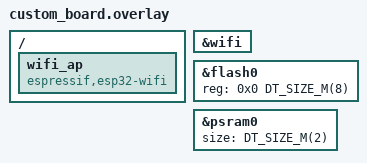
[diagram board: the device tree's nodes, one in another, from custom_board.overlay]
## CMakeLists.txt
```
# SPDX-License-Identifier: Apache-2.0
cmake_minimum_required(VERSION 3.20.0)
find_package(Zephyr REQUIRED HINTS $ENV{ZEPHYR_BASE})

project(http_get)

target_sources(app PRIVATE
  ./src/http_get.c
  # src/settings_thread.c
  ./src/nvs_usage.c
)

include(${ZEPHYR_BASE}/samples/net/common/common.cmake)

set(gen_dir ${ZEPHYR_BINARY_DIR}/include/generated/)

generate_inc_file_for_target(
    app
    src/globalsign_r1.der
    ${gen_dir}/globalsign_r1.der.inc
    )
```

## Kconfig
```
#
# Copyright (c) 2025 Ezurio
#
# SPDX-License-Identifier: Apache-2.0
#

source "samples/net/common/Kconfig"
source "Kconfig.zephyr"

config SAMPLE_USE_SPIRAM
	bool "Use SPIRAM to allocate MbedTLS heap, network stacks and some variables"
	default y
	depends on ESP_SPIRAM
	select ESP32_WIFI_NET_ALLOC_SPIRAM
	select MBEDTLS_HEAP_CUSTOM_SECTION
```

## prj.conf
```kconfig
# General config
CONFIG_MAIN_STACK_SIZE=4096
CONFIG_REQUIRES_FULL_LIBC=y
CONFIG_HEAP_MEM_POOL_SIZE=100000

CONFIG_ZVFS_POLL_MAX=4
# Networking config
CONFIG_NETWORKING=y
CONFIG_NET_IPV4=y
CONFIG_NET_IPV6=y
CONFIG_NET_TCP=y
CONFIG_NET_SOCKETS=y

CONFIG_POSIX_API=y

# CONFIG_DNS_RESOLVER=y
# CONFIG_DNS_SERVER_IP_ADDRESSES=y
# CONFIG_DNS_SERVER1="192.0.2.2"

# Network driver config
CONFIG_TEST_RANDOM_GENERATOR=y

# Network address config
CONFIG_NET_CONFIG_SETTINGS=y
CONFIG_NET_CONFIG_NEED_IPV4=y
CONFIG_NET_CONFIG_MY_IPV4_ADDR="192.0.2.1"
CONFIG_NET_CONFIG_PEER_IPV4_ADDR="192.0.2.2"
CONFIG_NET_CONFIG_MY_IPV4_GW=""

# Network debug config
CONFIG_NET_LOG=y

# Network (Configs)
# CONFIG_NET_TCP_WORKQ_STACK_SIZE=4096
CONFIG_NET_BUF_DATA_SIZE=256
CONFIG_NET_TX_STACK_SIZE=4096
CONFIG_NET_RX_STACK_SIZE=4096
# Networking
CONFIG_NETWORKING=y
CONFIG_NET_CONFIG_SETTINGS=y
CONFIG_NET_MGMT_EVENT_QUEUE_SIZE=10
# CONFIG_NET_TCP_WORKQ_STACK_SIZE=8192
CONFIG_NET_CONFIG_AUTO_INIT=n
# This is the maximum number of connections that can be active at any given time.
CONFIG_NET_MAX_CONN=12
CONFIG_NET_DHCPV4=y
CONFIG_NET_IPV4=y
CONFIG_NET_IF_MAX_IPV4_COUNT=1
CONFIG_NET_IPV6=n
CONFIG_NET_SOCKETS=y
CONFIG_NET_L2_ETHERNET=y
CONFIG_NET_L2_WIFI_MGMT=y
CONFIG_NET_MGMT=y
CONFIG_NET_MGMT_EVENT=y
CONFIG_NET_MGMT_EVENT_INFO=y
CONFIG_NET_MGMT_EVENT_STACK_SIZE=2048
CONFIG_NET_PKT_RX_COUNT=12
CONFIG_NET_PKT_TX_COUNT=12
CONFIG_NET_TCP=y
CONFIG_NET_MAX_CONTEXTS=6
CONFIG_NET_UDP=y

# Networking (DNS)
CONFIG_DNS_RESOLVER=y
CONFIG_DNS_RESOLVER_AI_MAX_ENTRIES=3

CONFIG_WIFI=y
CONFIG_WIFI_ESP32=y
CONFIG_ESP32_WIFI_STA_AUTO_DHCPV4=y
CONFIG_ESP32_WIFI_STA_RECONNECT=y
CONFIG_ESP32_WIFI_AP_STA_MODE=n
# CONFIG_WIFI_NM=y
# CONFIG_WIFI_NM_MAX_MANAGED_INTERFACES=2
# # Networking (Connection Manager)
# CONFIG_NET_CONNECTION_MANAGER=y
# CONFIG_NET_CONNECTION_MANAGER_CONNECTIVITY_WIFI_MGMT=y

# Shell
CONFIG_SHELL=n
CONFIG_SYS_HEAP_RUNTIME_STATS=y
# CONFIG_NET_STATISTICS=y
# CONFIG_NET_STATISTICS_TCP=y
# CONFIG_NET_STATISTICS_USER_API=y
CONFIG_THREAD_NAME=y
CONFIG_THREAD_STACK_INFO=n
# CONFIG_NET_SHELL=y
# CONFIG_NET_L2_WIFI_SHELL=y

# TLS configuration
CONFIG_MBEDTLS=y
CONFIG_MBEDTLS_BUILTIN=y
CONFIG_MBEDTLS_ENABLE_HEAP=y
# 60KB for MbedTLS HEAP
CONFIG_MBEDTLS_HEAP_SIZE=61440
CONFIG_MBEDTLS_SSL_MAX_CONTENT_LEN=7168
# CONFIG_MBEDTLS_SSL_MAX_CONTENT_LEN=7168
CONFIG_MBEDTLS_HASH_ALL_ENABLED=y
CONFIG_MBEDTLS_CMAC=y

CONFIG_NET_SOCKETS_SOCKOPT_TLS=y

# Debugging options
# CONFIG_MBEDTLS_DEBUG=y
# CONFIG_MBEDTLS_LOG_LEVEL_INF=y

# Logging
CONFIG_LOG=y
CONFIG_LOG_MODE_MINIMAL=y
CONFIG_LOG_MODE_IMMEDIATE=y
# CONFIG_LOG_BUFFER_SIZE=8000
# CONFIG_LOG_PROCESS_THREAD_STACK_SIZE=4096

CONFIG_NVS=y
# CONFIG_SETTINGS=y
# CONFIG_SETTINGS_RUNTIME=y
# CONFIG_SETTINGS_NVS=y

# Flash configuration settings.
CONFIG_FLASH=y
CONFIG_FLASH_MAP=y
CONFIG_FLASH_PAGE_LAYOUT=y
CONFIG_STREAM_FLASH=y
CONFIG_MPU_ALLOW_FLASH_WRITE=y
```

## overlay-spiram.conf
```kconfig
# SPIRAM configuration
CONFIG_ESP_SPIRAM=y
CONFIG_ESP32S3_DATA_CACHE_64KB=y
# CONFIG_SPIRAM_FETCH_INSTRUCTIONS=y
# CONFIG_SPIRAM_RODATA=y
CONFIG_ESP_SPIRAM_HEAP_SIZE=524288
# CONFIG_ESP32_WIFI_NET_ALLOC_SPIRAM=y
CONFIG_ESP_SPIRAM_MEMTEST=y
CONFIG_SPIRAM_MODE_QUAD=y
CONFIG_SPIRAM_SPEED_40M=y
# CONFIG_MBEDTLS_HEAP_CUSTOM_SECTION=y
```

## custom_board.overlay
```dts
&wifi {
	status = "okay";
};

/ {
	wifi_ap: wifi_ap {
		compatible = "espressif,esp32-wifi";
		status = "okay";
	};
};

/* 8MB flash */
&flash0 {
	reg = <0x0 DT_SIZE_M(8)>;
};

/* 2MB psram */
&psram0 {
	size = <DT_SIZE_M(2)>;
};
```

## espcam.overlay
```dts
&wifi {
	status = "okay";
};

/ {
	wifi_ap: wifi_ap {
		compatible = "espressif,esp32-wifi";
		status = "okay";
	};
};
```

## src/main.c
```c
#include <zephyr/kernel.h>
#include <zephyr/debug/coredump.h>

int main(int argc, char *argv[])
{
	printk("Init app\n");
	return 0;
}
```

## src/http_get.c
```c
/*
 * Copyright (c) 2017 Linaro Limited
 *
 * SPDX-License-Identifier: Apache-2.0
 */

#include <stdio.h>
#include <stdlib.h>

#if !defined(__ZEPHYR__)

#include <netinet/in.h>
#include <sys/socket.h>
#include <arpa/inet.h>
#include <unistd.h>
#include <netdb.h>

#else

#include <zephyr/net/socket.h>
#include <zephyr/kernel.h>
#include <zephyr/net/wifi_mgmt.h>

#if defined(CONFIG_NET_SOCKETS_SOCKOPT_TLS)
#include <zephyr/net/tls_credentials.h>
#include "ca_certificate.h"
#endif

#include <zephyr/logging/log.h>
LOG_MODULE_REGISTER(app, LOG_LEVEL_DBG);

#include "net_sample_common.h"

#endif /* __ZEPHYR__ */

#define MACSTR "%02X:%02X:%02X:%02X:%02X:%02X"

#define NET_EVENT_WIFI_MASK (NET_EVENT_WIFI_CONNECT_RESULT | NET_EVENT_WIFI_DISCONNECT_RESULT)

/* STA Mode Configuration */
#define WIFI_SSID "NETUNO"   /* Replace `SSID` with WiFi ssid. */
#define WIFI_PSK  "11311118" /* Replace `PASSWORD` with Router password. */

static struct net_if *sta_iface;
static struct wifi_connect_req_params sta_config;

/* HTTP server to connect to */
#define HTTP_HOST "google.com"
/* Port to connect to, as string */
#if defined(CONFIG_NET_SOCKETS_SOCKOPT_TLS)
#define HTTP_PORT "443"
#else
#define HTTP_PORT "80"
#endif
/* HTTP path to request */
#define HTTP_PATH "/"

#define SSTRLEN(s) (sizeof(s) - 1)
#define CHECK(r)                                                                                   \
	{                                                                                          \
		if (r < 0) {                                                                       \
			ret = r;                                                                   \
			LOG_DBG("Error: %d", (int)r);                                              \
			goto cleanup;                                                              \
		}                                                                                  \
	}

#define REQUEST "GET " HTTP_PATH " HTTP/1.1\r\nHost: " HTTP_HOST "\r\n\r\n"

#if defined(CONFIG_SAMPLE_USE_SPIRAM)
#define RAM_SECTION __attribute__((section(".ext_ram.bss")))
#else
#define RAM_SECTION
#endif

#define RESPONSE_BUFFER_SIZE 128
RAM_SECTION static char response[RESPONSE_BUFFER_SIZE];

static struct net_mgmt_event_callback cb;
K_SEM_DEFINE(sem_connected_to_internet, 0, 1);

static void wifi_event_handler(struct net_mgmt_event_callback *cb, uint32_t mgmt_event,
			       struct net_if *iface)
{
	switch (mgmt_event) {
	case NET_EVENT_WIFI_CONNECT_RESULT: {
		LOG_DBG("Connected to %s", WIFI_SSID);
		k_sem_give(&sem_connected_to_internet);
		break;
	}
	case NET_EVENT_WIFI_DISCONNECT_RESULT: {
		LOG_DBG("Disconnected from %s", WIFI_SSID);
		break;
	}
	default:
		break;
	}
}
void dump_addrinfo(const struct addrinfo *ai)
{
	LOG_DBG("addrinfo @%p: ai_family=%d, ai_socktype=%d, ai_protocol=%d, "
		"sa_family=%d, sin_port=%x",
		ai, ai->ai_family, ai->ai_socktype, ai->ai_protocol, ai->ai_addr->sa_family,
		ntohs(((struct sockaddr_in *)ai->ai_addr)->sin_port));
}

static int connect_to_wifi(void)
{
	if (!sta_iface) {
		LOG_DBG("STA: interface no initialized");
		return -EIO;
	}

	sta_config.ssid = (const uint8_t *)WIFI_SSID;
	sta_config.ssid_length = strlen(WIFI_SSID);
	sta_config.psk = (const uint8_t *)WIFI_PSK;
	sta_config.psk_length = strlen(WIFI_PSK);
	sta_config.security = WIFI_SECURITY_TYPE_PSK;
	sta_config.channel = WIFI_CHANNEL_ANY;
	sta_config.band = WIFI_FREQ_BAND_2_4_GHZ;

	LOG_DBG("Connecting to SSID: %s", sta_config.ssid);

	int ret = net_mgmt(NET_REQUEST_WIFI_CONNECT, sta_iface, &sta_config,
			   sizeof(struct wifi_connect_req_params));
	if (ret) {
		LOG_DBG("Unable to Connect to (%s). err=%d", WIFI_SSID, ret);
	}

	return ret;
}

int https_get()
{
	static struct addrinfo hints;
	struct addrinfo *res;
	int st, sock, ret = 0;

#if defined(CONFIG_NET_SOCKETS_SOCKOPT_TLS)
	tls_credential_add(CA_CERTIFICATE_TAG, TLS_CREDENTIAL_CA_CERTIFICATE, ca_certificate,
			   sizeof(ca_certificate));
#endif

	LOG_DBG("Preparing HTTP GET request for http://" HTTP_HOST ":" HTTP_PORT HTTP_PATH);

	hints.ai_family = AF_INET;
	hints.ai_socktype = SOCK_STREAM;
	st = getaddrinfo(HTTP_HOST, HTTP_PORT, &hints, &res);
	LOG_DBG("getaddrinfo status: %d", st);

	if (st != 0) {
		LOG_DBG("Unable to resolve address, quitting");
		return -ENETUNREACH;
	}

	dump_addrinfo(res);

#if defined(CONFIG_NET_SOCKETS_SOCKOPT_TLS)
	sock = socket(res->ai_family, res->ai_socktype, IPPROTO_TLS_1_2);
#else
	sock = socket(res->ai_family, res->ai_socktype, res->ai_protocol);
#endif
	CHECK(sock);
	LOG_DBG("sock = %d", sock);

	struct timeval timeout_optval = {
		.tv_sec = 5,
		.tv_usec = 0,
	};
	CHECK(setsockopt(sock, SOL_SOCKET, SO_RCVTIMEO, &timeout_optval, sizeof timeout_optval));

#if defined(CONFIG_NET_SOCKETS_SOCKOPT_TLS)
	sec_tag_t sec_tag_opt[] = {
		CA_CERTIFICATE_TAG,
	};
	CHECK(setsockopt(sock, SOL_TLS, TLS_SEC_TAG_LIST, sec_tag_opt, sizeof(sec_tag_opt)));

	CHECK(setsockopt(sock, SOL_TLS, TLS_HOSTNAME, HTTP_HOST, sizeof(HTTP_HOST)))
#endif
	LOG_WRN("Connecting to server...");
	CHECK(connect(sock, res->ai_addr, res->ai_addrlen));

	LOG_DBG("Connected! Sending request...");
	CHECK(send(sock, REQUEST, SSTRLEN(REQUEST), 0));

	int i = 0;
	char hexdump_str[64];
	while (1) {
		++i;
		int len = recv(sock, response, RESPONSE_BUFFER_SIZE, 0);

		if (len == -1) {
			break;
		}

		if (len < -1) {
			LOG_ERR("Could not recive bytes: err=%d", len);
			break;
		}

		if (len == 0) {
			LOG_DBG(" *** #fragments=%d", i);
			break;
		}

		snprintk(hexdump_str, 64, "Response (fragment=%d, length=%d):", i, len);
		LOG_HEXDUMP_DBG(response, RESPONSE_BUFFER_SIZE, hexdump_str);
	}
cleanup:
	freeaddrinfo(res);
	(void)close(sock);

	LOG_WRN("Close socket");

	return ret;
}

void https_get_thread(void *p1, void *p2, void *p3)
{
	printk(" ===> Starting HTTPS get sample\n");
	ARG_UNUSED(p1);
	ARG_UNUSED(p2);
	ARG_UNUSED(p3);

	net_mgmt_init_event_callback(&cb, wifi_event_handler, NET_EVENT_WIFI_MASK);
	net_mgmt_add_event_callback(&cb);

	/* Get STA interface in AP-STA mode. */
	sta_iface = net_if_get_wifi_sta();

	connect_to_wifi();

	do {
		LOG_DBG("Waiting to connect to wifi...");
	} while (k_sem_take(&sem_connected_to_internet, K_SECONDS(60)) != 0);

	while (1) {
		int err = https_get();
		if (err) {
			LOG_ERR("Could not get the https request: %d", err);
		}
		// k_msleep(2000);
	}
}

K_THREAD_DEFINE(https_get_thread_id, 12288, https_get_thread, NULL, NULL, NULL, 3, 0, 0);
```

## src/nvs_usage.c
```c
#include <zephyr/kernel.h>
#include <zephyr/device.h>
#include <string.h>
#include <zephyr/drivers/flash.h>
#include <zephyr/storage/flash_map.h>
#include <zephyr/fs/nvs.h>

#include <zephyr/logging/log.h>
LOG_MODULE_REGISTER(nvs, LOG_LEVEL_DBG);

static struct nvs_fs fs;

#define NVS_PARTITION        storage_partition
#define NVS_PARTITION_DEVICE FIXED_PARTITION_DEVICE(NVS_PARTITION)
#define NVS_PARTITION_OFFSET FIXED_PARTITION_OFFSET(NVS_PARTITION)

#define STRING_ID 1

#if defined(CONFIG_SAMPLE_USE_SPIRAM)
#define RAM_SECTION __attribute__((section(".ext_ram.bss")))
#else
#define RAM_SECTION
#endif

#define BUF_SIZE                       128
#define FLASH_READ_AMOUNT_BEFORE_WRITE 10000

RAM_SECTION int rc;
RAM_SECTION char buf[BUF_SIZE];

void nvs_sample_thread(void *p1, void *p2, void *p3)
{
	LOG_DBG(" ===> Starting NVS sample");
	ARG_UNUSED(p1);
	ARG_UNUSED(p2);
	ARG_UNUSED(p3);

	rc = 0;

	uint64_t *counter = (uint64_t *)buf;
	*counter = 0;

	for (int i = 8; i < BUF_SIZE; ++i) {
		buf[i] = i;
	}
	struct flash_pages_info info;

	/* define the nvs file system by settings with:
	 *	sector_size equal to the pagesize,
	 *	3 sectors
	 *	starting at NVS_PARTITION_OFFSET
	 */
	fs.flash_device = NVS_PARTITION_DEVICE;
	if (!device_is_ready(fs.flash_device)) {
		LOG_DBG("Flash device %s is not ready", fs.flash_device->name);
		return;
	}
	fs.offset = NVS_PARTITION_OFFSET;
	rc = flash_get_page_info_by_offs(fs.flash_device, fs.offset, &info);
	if (rc) {
		LOG_DBG("Unable to get page info, rc=%d", rc);
		return;
	}
	fs.sector_size = info.size;
	fs.sector_count = 48U;

	rc = nvs_mount(&fs);
	if (rc) {
		LOG_DBG("Flash Init failed, rc=%d", rc);
		return;
	}
	rc = nvs_read(&fs, STRING_ID, &buf, sizeof(buf));
	if (rc > 0) {
		LOG_DBG("Found counter: %" PRId64, *counter);
	}

	while (1) {
		LOG_DBG(" ~~> Reading flash (reading amount: %d)", FLASH_READ_AMOUNT_BEFORE_WRITE);

		*counter += 1;

		for (int i = 8; i < BUF_SIZE; ++i) {
			buf[i] = *counter;
		}

		(void)nvs_write(&fs, STRING_ID, &buf, sizeof(buf));

		for (int i = 0; i < FLASH_READ_AMOUNT_BEFORE_WRITE; ++i) {
			rc = nvs_read(&fs, STRING_ID, &buf, sizeof(buf));
			// k_busy_wait(100);
			k_yield();
		}

		if (rc > 0) { /* item was found, show it */
			LOG_DBG("Counter: %" PRId64, *counter);
		} else {
			LOG_DBG("Could not read flash. err=%d", rc);
		}

		k_msleep(100);
	}
}

K_THREAD_DEFINE(nvs_sample_thread_id, 4096, nvs_sample_thread, NULL, NULL, NULL, 3, 0, 5000);
```

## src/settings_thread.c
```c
/*
 * Copyright (c) 2019 Nordic Semiconductor ASA
 *
 * SPDX-License-Identifier: Apache-2.0
 */

#include <stdio.h>
#include <string.h>

#include <zephyr/settings/settings.h>

#include <zephyr/sys/printk.h>
#include <zephyr/kernel.h>

#define STORAGE_PARTITION    storage_partition
#define STORAGE_PARTITION_ID FIXED_PARTITION_ID(STORAGE_PARTITION)

#define GAMMA_DEFAULT_VAl  0
#define FAIL_MSG           "fail (err %d)\n"
#define SECTION_BEGIN_LINE "\n=================================================\n"
/* Default values are assigned to settings values consuments
 * All of them will be overwritten if storage contain proper key-values
 */

#define RAM_SECTION __attribute__((section(".ext_ram.bss")))
// #define RAM_SECTION

RAM_SECTION uint8_t angle_val;
RAM_SECTION uint64_t length_val;
RAM_SECTION uint16_t length_1_val;
RAM_SECTION uint32_t length_2_val;
RAM_SECTION int32_t voltage_val;
RAM_SECTION char source_name_val[6];

int alpha_handle_set(const char *name, size_t len, settings_read_cb read_cb, void *cb_arg);
int alpha_handle_commit(void);
int alpha_handle_export(int (*cb)(const char *name, const void *value, size_t val_len));

int beta_handle_set(const char *name, size_t len, settings_read_cb read_cb, void *cb_arg);
int beta_handle_commit(void);
int beta_handle_export(int (*cb)(const char *name, const void *value, size_t val_len));
int beta_handle_get(const char *name, char *val, int val_len_max);

/* dynamic main tree handler */
struct settings_handler alph_handler = {.name = "alpha",
					.h_get = NULL,
					.h_set = alpha_handle_set,
					.h_commit = alpha_handle_commit,
					.h_export = alpha_handle_export};

/* static subtree handler */
SETTINGS_STATIC_HANDLER_DEFINE(beta, "alpha/beta", beta_handle_get, beta_handle_set,
			       beta_handle_commit, beta_handle_export);

int alpha_handle_set(const char *name, size_t len, settings_read_cb read_cb, void *cb_arg)
{
	const char *next;
	size_t next_len;
	int rc;

	if (settings_name_steq(name, "angle/1", &next) && !next) {
		if (len != sizeof(angle_val)) {
			return -EINVAL;
		}
		rc = read_cb(cb_arg, &angle_val, sizeof(angle_val));
		LOG_DBG("<alpha/angle/1> = %d", angle_val);
		return 0;
	}

	next_len = settings_name_next(name, &next);

	if (!next) {
		return -ENOENT;
	}

	if (!strncmp(name, "length", next_len)) {
		next_len = settings_name_next(name, &next);

		if (!next) {
			rc = read_cb(cb_arg, &length_val, sizeof(length_val));
			printk("<alpha/length> = %" PRId64 "\n", length_val);
			return 0;
		}

		if (!strncmp(next, "1", next_len)) {
			rc = read_cb(cb_arg, &length_1_val, sizeof(length_1_val));
			LOG_DBG("<alpha/length/1> = %d", length_1_val);
			return 0;
		}

		if (!strncmp(next, "2", next_len)) {
			rc = read_cb(cb_arg, &length_2_val, sizeof(length_2_val));
			LOG_DBG("<alpha/length/2> = %d", length_2_val);
			return 0;
		}

		return -ENOENT;
	}

	return -ENOENT;
}

int beta_handle_set(const char *name, size_t len, settings_read_cb read_cb, void *cb_arg)
{
	const char *next;
	size_t name_len;
	int rc;

	name_len = settings_name_next(name, &next);

	if (!next) {
		if (!strncmp(name, "voltage", name_len)) {
			rc = read_cb(cb_arg, &voltage_val, sizeof(voltage_val));
			LOG_DBG("<alpha/beta/voltage> = %d", voltage_val);
			return 0;
		}

		if (!strncmp(name, "source", name_len)) {
			if (len > sizeof(source_name_val) - 1) {
				printk("<alpha/beta/source> is not compatible "
				       "with the application\n");
				return -EINVAL;
			}
			rc = read_cb(cb_arg, source_name_val, sizeof(source_name_val));
			if (rc < 0) {
				return rc;
			} else if (rc > 0) {
				LOG_DBG("<alpha/beta/source> = %s", source_name_val);
			}
			return 0;
		}
	}

	return -ENOENT;
}

int alpha_handle_commit(void)
{
	LOG_DBG("loading all settings under <alpha> handler is done");
	return 0;
}

int alpha_handle_export(int (*cb)(const char *name, const void *value, size_t val_len))
{
	LOG_DBG("export keys under <alpha> handler");
	(void)cb("alpha/angle/1", &angle_val, sizeof(angle_val));
	(void)cb("alpha/length", &length_val, sizeof(length_val));
	(void)cb("alpha/length/1", &length_1_val, sizeof(length_1_val));
	(void)cb("alpha/length/2", &length_2_val, sizeof(length_2_val));

	return 0;
}

int beta_handle_export(int (*cb)(const char *name, const void *value, size_t val_len))
{
	LOG_DBG("export keys under <beta> handler");
	(void)cb("alpha/beta/voltage", &voltage_val, sizeof(voltage_val));
	(void)cb("alpha/beta/source", source_name_val, strlen(source_name_val) + 1);

	return 0;
}

int beta_handle_commit(void)
{
	LOG_DBG("loading all settings under <beta> handler is done");
	return 0;
}

int beta_handle_get(const char *name, char *val, int val_len_max)
{
	const char *next;

	if (settings_name_steq(name, "source", &next) && !next) {
		val_len_max = MIN(val_len_max, strlen(source_name_val));
		memcpy(val, source_name_val, val_len_max);
		return val_len_max;
	}

	return -ENOENT;
}

static void example_save_and_load_basic(void)
{
	int i, rc;
	int32_t val_s32;

	length_val = 100;
	length_1_val = 40;
	length_2_val = 60;
	voltage_val = -3000;
	source_name_val[0] = '\0';

	printk(SECTION_BEGIN_LINE);
	LOG_DBG("basic load and save using registered handlers");
	/* load all key-values at once
	 * In case a key-value doesn't exist in the storage
	 * default values should be assigned to settings consuments variable
	 * before any settings load call
	 */
	LOG_DBG("\nload all key-value pairs using registered handlers");
	settings_load();

	val_s32 = voltage_val - 25;
	/* save certain key-value directly*/
	printk("\nsave <alpha/beta/voltage> key directly: ");
	rc = settings_save_one("alpha/beta/voltage", (const void *)&val_s32, sizeof(val_s32));
	if (rc) {
		printk(FAIL_MSG, rc);
	}

	LOG_DBG("OK.");

	printk("\nload <alpha/beta> key-value pairs using registered "
	       "handlers\n");
	settings_load_subtree("alpha/beta");

	/* save only modified values
	 * or those that were not saved
	 * before
	 */
	i = strlen(source_name_val);
	if (i < sizeof(source_name_val) - 1) {
		source_name_val[i] = 'a' + i;
		source_name_val[i + 1] = 0;
	} else {
		source_name_val[0] = 0;
	}

	angle_val += 1;

	LOG_DBG("\nsave all key-value pairs using registered handlers");
	settings_save();

	if (++length_1_val > 100) {
		length_1_val = 0;
	}

	if (--length_2_val > 100) {
		length_2_val = 100;
	}

	/*---------------------------
	 * save only modified values
	 * or those that were deleted
	 * before
	 */
	LOG_DBG("\nload all key-value pairs using registered handlers");
	settings_save();
}

struct direct_length_data {
	uint64_t length;
	uint16_t length_1;
	uint32_t length_2;
};

static int direct_loader(const char *name, size_t len, settings_read_cb read_cb, void *cb_arg,
			 void *param)
{
	const char *next;
	size_t name_len;
	int rc;
	struct direct_length_data *dest = (struct direct_length_data *)param;

	printk("direct load: ");

	name_len = settings_name_next(name, &next);

	if (name_len == 0) {
		rc = read_cb(cb_arg, &(dest->length), sizeof(dest->length));
		LOG_DBG("<alpha/length>");
		return 0;
	}

	name_len = settings_name_next(name, &next);
	if (next) {
		LOG_DBG("nothing");
		return -ENOENT;
	}

	if (!strncmp(name, "1", name_len)) {
		rc = read_cb(cb_arg, &(dest->length_1), sizeof(dest->length_1));
		LOG_DBG("<alpha/length/1>");
		return 0;
	}

	if (!strncmp(name, "2", name_len)) {
		rc = read_cb(cb_arg, &(dest->length_2), sizeof(dest->length_2));
		LOG_DBG("<alpha/length/2>");
		return 0;
	}

	LOG_DBG("nothing");
	return -ENOENT;
}

static void example_direct_load_subtree(void)
{
	struct direct_length_data dld;
	int rc;

	/* load subtree directly using call-specific handler `direct_loader'
	 * This handler loads subtree values to call-specific structure of type
	 * 'direct_length_data`.
	 */
	printk(SECTION_BEGIN_LINE);
	LOG_DBG("loading subtree to destination provided by the caller\n");
	rc = settings_load_subtree_direct("alpha/length", direct_loader, (void *)&dld);
	if (rc == 0) {
		printk("  direct.length = %" PRId64 "\n", dld.length);
		LOG_DBG("  direct.length_1 = %d", dld.length_1);
		LOG_DBG("  direct.length_2 = %d", dld.length_2);
	} else {
		LOG_DBG("  direct load fails unexpectedly");
	}
}

struct direct_immediate_value {
	size_t len;
	void *dest;
	uint8_t fetched;
};

static int direct_loader_immediate_value(const char *name, size_t len, settings_read_cb read_cb,
					 void *cb_arg, void *param)
{
	const char *next;
	size_t name_len;
	int rc;
	struct direct_immediate_value *one_value = (struct direct_immediate_value *)param;

	name_len = settings_name_next(name, &next);

	if (name_len == 0) {
		if (len == one_value->len) {
			rc = read_cb(cb_arg, one_value->dest, len);
			if (rc >= 0) {
				one_value->fetched = 1;
				LOG_DBG("immediate load: OK.");
				return 0;
			}

			printk(FAIL_MSG, rc);
			return rc;
		}
		return -EINVAL;
	}

	/* other keys aren't served by the callback
	 * Return success in order to skip them
	 * and keep storage processing.
	 */
	return 0;
}

int load_immediate_value(const char *name, void *dest, size_t len)
{
	int rc;
	struct direct_immediate_value dov;

	dov.fetched = 0;
	dov.len = len;
	dov.dest = dest;

	rc = settings_load_subtree_direct(name, direct_loader_immediate_value, (void *)&dov);
	if (rc == 0) {
		if (!dov.fetched) {
			rc = -ENOENT;
		}
	}

	return rc;
}

static void example_without_handler(void)
{
	uint8_t val_u8;
	int rc;

	printk(SECTION_BEGIN_LINE);
	LOG_DBG("Service a key-value pair without dedicated handlers\n");
	rc = load_immediate_value("gamma", &val_u8, sizeof(val_u8));
	if (rc == -ENOENT) {
		val_u8 = GAMMA_DEFAULT_VAl;
		LOG_DBG("<gamma> = %d (default)", val_u8);
	} else if (rc == 0) {
		LOG_DBG("<gamma> = %d", val_u8);
	} else {
		printk("unexpected" FAIL_MSG, rc);
	}

	val_u8++;

	printk("save <gamma> key directly: ");
	rc = settings_save_one("gamma", (const void *)&val_u8, sizeof(val_u8));
	if (rc) {
		printk(FAIL_MSG, rc);
	} else {
		LOG_DBG("OK.");
	}
}

static void example_initialization(void)
{
	int rc;

#if defined(CONFIG_SETTINGS_FILE)
	FS_LITTLEFS_DECLARE_DEFAULT_CONFIG(cstorage);

	/* mounting info */
	static struct fs_mount_t littlefs_mnt = {.type = FS_LITTLEFS,
						 .fs_data = &cstorage,
						 .storage_dev = (void *)STORAGE_PARTITION_ID,
						 .mnt_point = "/ff"};

	rc = fs_mount(&littlefs_mnt);
	if (rc != 0) {
		LOG_DBG("mounting littlefs error: [%d]", rc);
	} else {

		rc = fs_unlink(CONFIG_SETTINGS_FILE_PATH);
		if ((rc != 0) && (rc != -ENOENT)) {
			LOG_DBG("can't delete config file%d", rc);
		} else {
			LOG_DBG("FS initialized: OK");
		}
	}
#endif

	rc = settings_subsys_init();
	if (rc) {
		LOG_DBG("settings subsys initialization: fail (err %d)", rc);
		return;
	}

	LOG_DBG("settings subsys initialization: OK.");

	rc = settings_register(&alph_handler);
	if (rc) {
		LOG_DBG("subtree <%s> handler registered: fail (err %d)", alph_handler.name, rc);
	}

	LOG_DBG("subtree <%s> handler registered: OK", alph_handler.name);
	LOG_DBG("subtree <alpha/beta> has static handler");
}

static void example_delete(void)
{
	uint64_t val_u64;
	int rc;

	printk(SECTION_BEGIN_LINE);
	LOG_DBG("Delete a key-value pair\n");

	rc = load_immediate_value("alpha/length", &val_u64, sizeof(val_u64));
	if (rc == 0) {
		LOG_DBG("  <alpha/length> value exist in the storage");
	}

	printk("delete <alpha/length>: ");
	rc = settings_delete("alpha/length");
	if (rc) {
		printk(FAIL_MSG, rc);
	} else {
		LOG_DBG("OK.");
	}

	rc = load_immediate_value("alpha/length", &val_u64, sizeof(val_u64));
	if (rc == -ENOENT) {
		printk("  Can't to load the <alpha/length> value as "
		       "expected\n");
	}
}

void example_runtime_usage(void)
{
	int rc;
	uint8_t injected_str[sizeof(source_name_val)] = "RT";

	printk(SECTION_BEGIN_LINE);
	LOG_DBG("Inject the value to the setting destination in runtime\n");

	rc = settings_runtime_set("alpha/beta/source", (void *)injected_str,
				  strlen(injected_str) + 1);

	printk("injected <alpha/beta/source>: ");
	if (rc) {
		printk(FAIL_MSG, rc);
	} else {
		LOG_DBG("OK.");
	}

	printk("  The settings destination off the key <alpha/beta/source> has "
	       "got value: \"%s\"\n\n",
	       source_name_val);

	/* set settings destination value "by hand" for next example */
	(void)strcpy(source_name_val, "rtos");

	printk(SECTION_BEGIN_LINE);
	LOG_DBG("Read a value from the setting destination in runtime\n");

	rc = settings_runtime_get("alpha/beta/source", (void *)injected_str,
				  strlen(injected_str) + 1);
	printk("fetched <alpha/beta/source>: ");
	if (rc < 0) {
		printk(FAIL_MSG, rc);
	} else {
		LOG_DBG("OK.");
	}

	printk("  String value \"%s\" was retrieved from the settings "
	       "destination off the key <alpha/beta/source>\n",
	       source_name_val);
}

void settings_thread(void *ptr1, void *ptr2, void *ptr3)
{
	int i;

	LOG_DBG("\n*** Settings usage example ***\n");

	/* settings initialization */
	example_initialization();

	k_msleep(5000);
	for (i = 0;; i++) {
		LOG_DBG("\n##############");
		printk("# iteration %d", i);
		LOG_DBG("\n##############");

		/*---------------------------------------------
		 * basic save and load using registered handler
		 */
		example_save_and_load_basic();

		/*-------------------------------------------------
		 *load subtree directly using call-specific handler
		 */
		example_direct_load_subtree();

		/*-------------------------
		 * delete certain key-value
		 */
		example_delete();

		/*---------------------------------------
		 * a key-value without dedicated handler
		 */
		example_without_handler();

		k_msleep(50);
	}

	/*------------------------------------------------------
	 * write and read settings destination using runtime API
	 */
	example_runtime_usage();

	return;
}

K_THREAD_DEFINE(settings_thread_id, 2048, settings_thread, NULL, NULL, NULL, 3, 0, 0);
```
